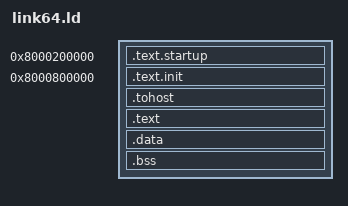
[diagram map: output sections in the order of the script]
OUTPUT_ARCH( "riscv" )
ENTRY(_start)

SECTIONS
{
  . = 0x8000200000;
  .text.startup : { *(.text.startup) }
  . = 0x8000800000;
  .text.init : { *(.text.init) }
  . = ALIGN(0x1000);
  .tohost : { *(.tohost) }
  . = ALIGN(0x1000);
  .text : { *(.text) }
  . = ALIGN(0x1000);
  .data : { *(.data) }
  .bss : { *(.bss) }
  _end = .;
}

